# TOP_AURORA_TX register map
Vendor: Texas Instruments
Peripheral module from a debugger description file (folder awr29xx).
Registers are 32-bit, read-write, no defined reset value unless marked. A register's access mark holds for its fields unless they carry their own. Offsets are as the file gives them; lines under a group give offsets from that group; [hi:lo] are bit positions; {n}, {i} and the like mark numbered series; 'fields as' and 'values as' point back to an identical list; <NAME> marks a mode.

## TOP_AURORA_TX
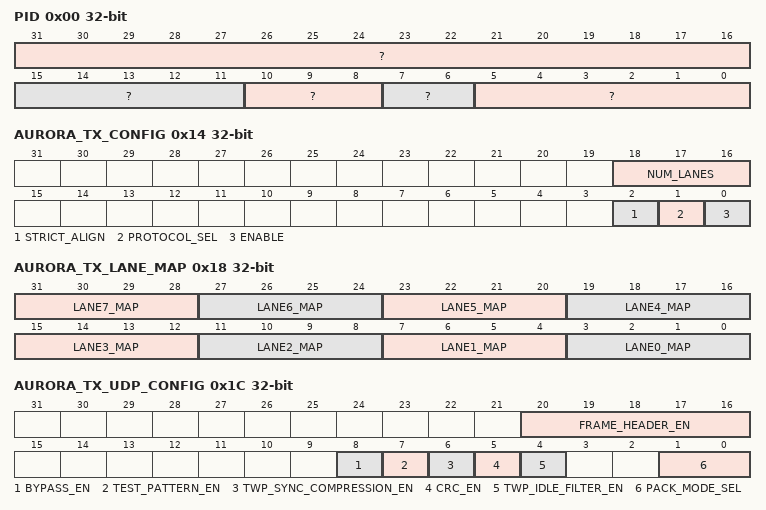
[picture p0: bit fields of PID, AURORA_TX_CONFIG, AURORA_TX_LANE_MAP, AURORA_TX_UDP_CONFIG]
0x00 PID ro
  [31:16] ?, [15:11] ?, [10:8] ?, [7:6] ?, [5:0] ?
0x14 AURORA_TX_CONFIG
  [18:16] NUM_LANES — Selects the number of lanes for trasnmission 0 : 1 Lane 1 : 2 Lanes 7 : 8Lanes
  [2] STRICT_ALIGN — Enable Aurora Strict Alingment Rules
  [1] PROTOCOL_SEL — Selects if the IP is in 8b/10b OR 64b/66b mode. 0 : 8b/10b 1 : 64b/66b
  [0] ENABLE — Selects if the IP is in 8b/10b OR 64b/66b mode. 0 : 8b/10b 1 : 64b/66b
0x18 AURORA_TX_LANE_MAP
  [31:28] LANE7_MAP — These 3 bits determine the logical lane that is transported over the physical lane 7. 000 : Logical lane 0 is transported over physical lane 7 001 : Logical lane 1 is transported over physical lane 7. .. 111 : Logical lane 7 is transported over physical lane 7.
  [27:24] LANE6_MAP — These 3 bits determine the logical lane that is transported over the physical lane 6. 000 : Logical lane 0 is transported over physical lane 6 001 : Logical lane 1 is transported over physical lane 6. .. 111 : Logical lane 7 is transported over physical lane 6.
  [23:20] LANE5_MAP — These 3 bits determine the logical lane that is transported over the physical lane 5. 000 : Logical lane 0 is transported over physical lane 5 001 : Logical lane 1 is transported over physical lane 5. .. 111 : Logical lane 7 is transported over physical lane 5.
  [19:16] LANE4_MAP — These 3 bits determine the logical lane that is transported over the physical lane 4. 000 : Logical lane 0 is transported over physical lane 4. 001 : Logical lane 1 is transported over physical lane 4. .. 111 : Logical lane 7 is transported over physical lane 4.
  [15:12] LANE3_MAP — These 3 bits determine the logical lane that is transported over the physical lane 3. 000 : Logical lane 0 is transported over physical lane 3 001 : Logical lane 1 is transported over physical lane 3. .. 111 : Logical lane 7 is transported over physical lane 3.
  [11:8] LANE2_MAP — These 3 bits determine the logical lane that is transported over the physical lane 2. 000 : Logical lane 0 is transported over physical lane 2 001 : Logical lane 1 is transported over physical lane 2. .. 111 : Logical lane 7 is transported over physical lane 2.
  [7:4] LANE1_MAP — These 3 bits determine the logical lane that is transported over the physical lane 1. 000 : Logical lane 0 is transported over physical lane 1 001 : Logical lane 1 is transported over physical lane 1. .. 111 : Logical lane 7 is transported over physical lane 1.
  [3:0] LANE0_MAP — These 3 bits determine the logical lane that is transported over the physical lane 0. 000 : Logical lane 0 is transported over physical lane 0. 001 : Logical lane 0 is transported over physical lane 1 .. 111 : Logical lane 7 is transported over physical lane 0.
0x1C AURORA_TX_UDP_CONFIG
  [20:16] FRAME_HEADER_EN — Header Enable configuration 0x0 : Disable Header transmission 0x1 - 0x10 : Number of 32 bit Header to be transmmited
  [8] BYPASS_EN — Writing a value of 1'b1 : Bypass the aurora protocol. - No aurora framing is done 1'b0 : Normal Mode - Framing is done as per aurora protocol
  [7] TEST_PATTERN_EN — Writing a value of 1'b1: Enable the test pattern generation when the aurora transmitter is in IDLE state.
  [6] TWP_SYNC_COMPRESSION_EN — Writing a value of 1'b1 : Enables the compression of incoming synchronisation packets. This allows only a configurable number of TWP synchronization packets define by AURORA_TX_TWP_SYNC_CNT::AURORA_TX_TWP_SYNC_CNT_SYNC_CNT to be send through aurora interface. 1'b0 : Disable the TWP padding packet filter.
  [5] CRC_EN — Writing a value of 1'b1 : Enable the UDP CRC calculation 1'b0 : Disable UDP CRC calculation
  [4] TWP_IDLE_FILTER_EN — Writing a value of 1'b1 : Filters out the incoming TWP Padding Packet from being send via aurora interface. 1'b0 : Disable the TWP padding packet filter.
  [1:0] PACK_MODE_SEL — Configure to select AURORATX_UDP_SIZE format 0: Number of TWP Packets 1 : Number of Bytes 3: SW only
0x20 AURORA_TX_UDP_SIZE
  [31:0] SIZE — Configure the number of TWP packets or data bytes to be sent as one packet based on AURORATX_CTRL::PACK_MODE. If PACK_MODE=1 Value configure should be multiple of 4 Bytes.
{0x24+4i} AURORA_TX_UDP_FRAME_HEADER{i} (i=0..15)
  [31:0] DATA — 32 bit DATA Sent out as Frame Header
0x64 AURORA_TX_UFC_MSG_CTRL
  [0] UFC_MSG_SENT_STS — This bit indicates that the message send triggered by the SEND_MSG bit has been completed. Read 1 : Either a hardware or software UFC event occurred. Read 0 : No UFC event occurred. Write 0 : No effect. Write 1 : Clears this bit. This bit is reset when the SEND_MSG bit is set.
0x68 AURORA_TX_UFC_MESSAGE0
  [31:0] MESSAGE0 — This register contains the octets 0 through 3 of the UFC message. All octets have a default value of 0x0A.
0x6C AURORA_TX_UFC_MESSAGE1
  [31:0] MESSAGE1 — This register contains the octets 4 through 7 of the UFC message. All octets have a default value of 0x0A.
0x70 AURORA_TX_TWP_SYNC_CNT
  [9:0] SYNC_CNT — Number of TWP Sync Packet that would be sent if AURORA_TX_UDP_CONFIG::A_TX_UDP_CONFIG_TWP_SYNC_COMPRESSION_EN is 0x1. (Min Value 2)
0x80 AURORA_TX_INITIALIZE_REQ
  [1] TX_INIT — The single bit input to trigger the initialization sequence. Asserting this bit starts Tx process.
0x84 AURORA_TX_UFC_MSG_REQ
  [0] SEND_MSG — The bit that triggers the controller to send the MESSAGE0 and MESSAGE1 register contents as a UFC packet.
0x88 AURORA_TX_FLUSH_REQ
  [0] TRIGGER — Selects the number of lanes for trasnmission 0 : 1 Lane 1 : 2 Lanes 7 : 8Lanes
0x8C AURORA_TX_EOP_REQ
  [0] TRIGGER — SW End of Packet trigger to aurora dataframer.
0x90 AURORA_TX_DATA_START_REQ
  [1] DATA_START — The single bit input to trigger the initialization sequence. Asserting this bit starts Tx process.
0x94 AURORA_TX_DATA_STOP_REQ
  [1] DATA_STOP — The single bit input to trigger the Start of Data Transmission
0x98 AURORA_TX_TESTPATTERN_START_REQ
  [1] TEST_PATTERN_START — The single bit input to trigger the Stop of Data Transmission
0x9C AURORA_TX_TESTPATTERN_STOP_REQ
  [1] TEST_PATTERN_STOP — The single bit input to trigger the Start of TestPattern Transmission
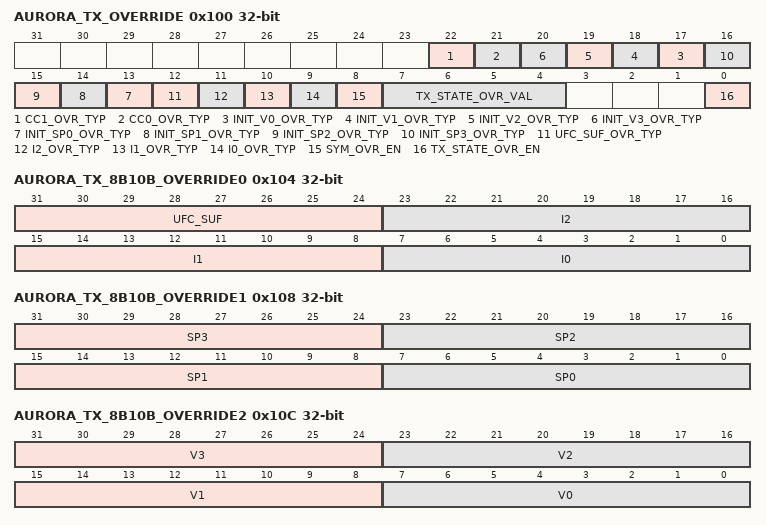
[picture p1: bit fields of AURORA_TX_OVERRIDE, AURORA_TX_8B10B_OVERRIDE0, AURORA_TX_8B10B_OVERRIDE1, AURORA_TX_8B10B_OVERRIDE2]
0x100 AURORA_TX_OVERRIDE
  [22] CC1_OVR_TYP — This read write bit indicates whether the CC1_OVR_TYP symbol is a /D/ octet or /K/ octet. 1 : Indicates a /K/ octet. 0 : Indicates a /D/ octet.
  [21] CC0_OVR_TYP — This read write bit indicates whether the CC0_OVR_TYP symbol is a /D/ octet or /K/ octet. 1 : Indicates a /K/ octet. 0 : Indicates a /D/ octet.
  [n+17] INIT_V{n}_OVR_TYP (n=0..3) — This read write bit indicates whether the INIT_V{n}_OVR_TYP symbol is a /D/ octet or /K/ octet. 1 : Indicates a /K/ octet. 0 : Indicates a /D/ octet.
  [n+13] INIT_SP{n}_OVR_TYP (n=0..3) — This read write bit indicates whether the INIT_SP{n}_OVR_TYP symbol is a /D/ octet or /K/ octet. 1 : Indicates a /K/ octet. 0 : Indicates a /D/ octet.
  [12] UFC_SUF_OVR_TYP — This read write bit indicates whether the UFC_SUF_OVR_TYP symbol is a /D/ octet or /K/ octet. 1 : Indicates a /K/ octet. 0 : Indicates a /D/ octet.
  [11] I2_OVR_TYP — This read write bit indicates whether the I2_OVR symbol is a /D/ octet or /K/ octet. 1 : Indicates a /K/ octet. 0 : Indicates a /D/ octet.
  [10] I1_OVR_TYP — This read write bit indicates whether the I1_OVR symbol is a /D/ octet or /K/ octet. 1 : Indicates a /K/ octet. 0 : Indicates a /D/ octet.
  [9] I0_OVR_TYP — This read write bit indicates whether the I0_OVR symbol is a /D/ octet or /K/ octet. 1 : Indicates a /K/ octet. 0 : Indicates a /D/ octet.
  [8] SYM_OVR_EN — This read write bit allows the symbols used in the various sequences to be overridden with the values used in the AURORA_TX_SYM register.
  [7:4] TX_STATE_OVR_VAL — These bits take effect to enforce a certain transmission state if the TX_ST_OVR_EN bit is set. The states are enforced as per the following bit values: 0000 : Reset, no transmission. 0001 : Initialization 0010 : Clock Compensation 0011 : Idle 0100 : UFC 0101 : Run (data) 0110 : Test (data) 0111 : Reserved . 1111 : Reserved
  [0] TX_STATE_OVR_EN — This read write bit allows the user to force the IP to remain in a given transmission state. The enforced transmission state is defined by the TX_ST_OVR bits.
0x104 AURORA_TX_8B10B_OVERRIDE0
  [31:24] UFC_SUF — The 8B/10B protocol defines Start of User Flow Control PDU symbol /SUF/. The value defined in the octet here allows this value to be overridden. The value defined here will be effective whenever the User Flow Control packet is transmitted. Default value of this octet is /SUF/ (/SUF/ <=> /K28.4/ <=> 0x9C). This value is effective only if the SYM_OVR_EN bit in the AURORA_TX_OVERRIDE register is set.
  [23:16] I2 — The 8B/10B protocol defines three symbols - /K/, /R/ and /A/ that can be used in the Idle (/I/) sequence. The value defined here will be effective whenever the Idle sequence is used during any transmission state. Default value of this octet is /R/ (/R/ <=> /K28.0/ <=> 0x1C). This value is effective only if the SYM_OVR_EN bit in the AURORA_TX_OVERRIDE register is set.
  [15:8] I1 — The 8B/10B protocol defines three symbols - /K/, /R/ and /A/ that can be used in the Idle (/I/) sequence. The value defined in the octet here allows one of the three to be overridden. The value defined here will be effective whenever the Idle sequence is used during any transmission state. Default value of this octet is /K/ (/K/ <=> /K28.5/ <=> 0xBC). This value is effective only if the SYM_OVR_EN bit in the AURORA_TX_OVERRIDE register is set.
  [7:0] I0 — The 8B/10B protocol defines three symbols - /K/, /R/ and /A/ that can be used in the Idle (/I/) sequence. The value defined here will be effective whenever the Idle sequence is used during any transmission state. Default value of this octet is /A/ (/A/ <=> /K28.3/ <=> 0x7C). This value is effective only if the SYM_OVR_EN bit in the AURORA_TX_OVERRIDE register is set.
0x108 AURORA_TX_8B10B_OVERRIDE1
  [31:24] SP3 — The 8B/10B protocol defines the /D10.2/ as the fourth octet to be used in the Sync Polarity (/SP/) sequence during lane initialization. The value defined in the octet here allows the fourth octet to be overridden. Default value of this octet is /D10.2/ <=> 0x4A. This value will be effective whenever the Sync Polarity sequence is used during the INIT transmission state. This value is effective only if the SYM_OVR_EN bit in the AURORA_TX_OVERRIDE register is set.
  [23:16] SP2 — The 8B/10B protocol defines the /D10.2/ as the third octet to be used in the Sync Polarity (/SP/) sequence during lane initialization. The value defined in the octet here allows the third octet to be overridden. Default value of this octet is /D10.2/ <=> 0x4A. This value will be effective whenever the Sync Polarity sequence is used during the INIT transmission state. This value is effective only if the SYM_OVR_EN bit in the AURORA_TX_OVERRIDE register is set.
  [15:8] SP1 — The 8B/10B protocol defines the /D10.2/ as the second octet to be used in the Sync Polarity (/SP/) sequence during lane initialization. The value defined in the octet here allows the second octet to be overridden. Default value of this octet is /D10.2/ <=> 0x4A. This value will be effective whenever the Sync Polarity sequence is used during the INIT transmission state. This value is effective only if the SYM_OVR_EN bit in the AURORA_TX_OVERRIDE register is set.
  [7:0] SP0 — The 8B/10B protocol defines the /K28.5/ as the first octet to be used in the Sync Polarity (/SP/) sequence during lane initialization. The value defined in the octet here allows the first octet to be overridden. Default value of this octet is /K28.5/ <=> 0xBC. This value will be effective whenever the Sync Polarity sequence is used during the INIT transmission state. This value is effective only if the SYM_OVR_EN bit in the AURORA_TX_OVERRIDE register is set.
0x10C AURORA_TX_8B10B_OVERRIDE2
  [31:24] V3 — The 8B/10B protocol defines the /D8.7/ as the fourth octet to be used in the Verification sequence during lane initialization. The value defined in the octet here allows the fourth octet to be overridden. Default value of this octet is /D8.7/ <=> 0xE8. This value will be effective whenever the Verification sequence is used during the INIT transmission state. This value is effective only if the SYM_OVR_EN bit in the AURORA_TX_OVERRIDE register is set.
  [23:16] V2 — The 8B/10B protocol defines the /D8.7/ as the third octet to be used in the Verification sequence during lane initialization. The value defined in the octet here allows the third octet to be overridden. Default value of this octet is /D8.7/ <=> 0xE8. This value will be effective whenever the Verification sequence is used during the INIT transmission state. This value is effective only if the SYM_OVR_EN bit in the AURORA_TX_OVERRIDE register is set.
  [15:8] V1 — The 8B/10B protocol defines the /D8.7/ as the second octet to be used in the Verification sequence during lane inititialization. The value defined in the octet here allows the second octet to be overridden. Default value of this octet is /D8.7/ <=> 0xE8. This value will be effective whenever the Verification sequence is used during the INIT transmission state. This value is effective only if the SYM_OVR_EN bit in the AURORA_TX_OVERRIDE register is set.
  [7:0] V0 — The 8B/10B protocol defines the /K28.5/ as the first octet to be used in the Verification sequence during lane inititialization. The value defined in the octet here allows the first octet to be overridden. Default value of this octet is /K28.5/ <=> 0xBC. This value will be effective whenever the Verification sequence is used during the INIT transmission state. This value is effective only if the SYM_OVR_EN bit in the AURORA_TX_OVERRIDE register is set.
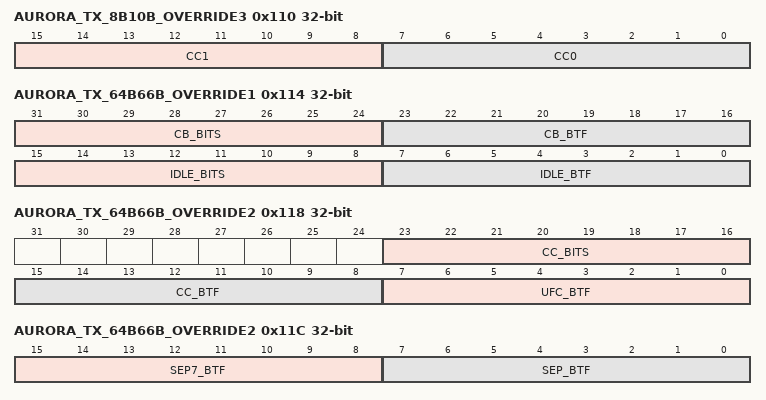
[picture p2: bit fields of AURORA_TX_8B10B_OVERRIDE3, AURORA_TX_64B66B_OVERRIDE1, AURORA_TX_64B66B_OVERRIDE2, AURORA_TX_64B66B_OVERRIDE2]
0x110 AURORA_TX_8B10B_OVERRIDE3
  [15:8] CC1 — The 8B/10B protocol defines the /K23.7/ as the second octet to be used in the Clock Compensation sequence. The value defined in the octet here allows the second octet to be overridden. Default value of this octet is /K23.7/ <=> 0xF7. This value will be effective whenever the Verification sequence is used during the Clock Compensation transmission state. This value is effective only if the SYM_OVR_EN bit in the AURORA_TX_OVERRIDE register is set.
  [7:0] CC0 — The 8B/10B protocol defines the /K23.7/ as the first octet to be used in the Clock Compensation sequence. The value defined in the octet here allows the first octet to be overridden. Default value of this octet is /K23.7/ <=> 0xF7. This value will be effective whenever the Verification sequence is used during the Clock Compensation transmission state. This value is effective only if the SYM_OVR_EN bit in the AURORA_TX_OVERRIDE register is set.
0x114 AURORA_TX_64B66B_OVERRIDE1
  [31:24] CB_BITS — The 64B/66B protocol defines the CC, CB, NR, SA bits for all the type of Idle Blocks. This field may be overriden with the values defined here. These bits are used during Channel Bonding. Bit 8 overrides the CC bit (bit 10 of 64B/66B block code), Bit 9 overrides the CB bit (bit 11 of 64B/66B block code), Bit 10 overrides the NR bit (bit 12 of 64B/66B block code), Bit 11 overrides the SA bit (bit 13 of 64B/66B block code), Bits 12:15 override the '0000' bits (bits [14:17] of 64B/66B block code). This field is effective only if the SYM_OVR_EN bit in the AURORA_TX_OVERRIDE register is set. This field is applicable only in the 64B/66B protocol mode.
  [23:16] CB_BTF — The 64B/66B protocol defines the value of 0x78 as the BTF for all the types of Idle code blocks. The value given in this field may be used to override the BTF for the Channel Bonding code blocks. This value is effective only if the SYM_OVR_EN bit in the AURORA_TX_OVERRIDE register is set. This field is applicable only in the 64B/66B protocol mode.
  [15:8] IDLE_BITS — The 64B/66B protocol defines the CC, CB, NR, SA bits for all the type of Idle Blocks. This field may be overriden with the values defined here. Bit 8 overrides the CC bit (bit 10 of 64B/66B block code), Bit 9 overrides the CB bit (bit 11 of 64B/66B block code), Bit 10 overrides the NR bit (bit 12 of 64B/66B block code), Bit 11 overrides the SA bit (bit 13 of 64B/66B block code), Bits 12:15 override the '0000' bits (bits [14:17] of 64B/66B block code). This field is effective only if the SYM_OVR_EN bit in the AURORA_TX_OVERRIDE register is set. This field is applicable only in the 64B/66B protocol mode.
  [7:0] IDLE_BTF — The 64B/66B protocol defines the value of 0x78 as the BTF for all the types of Idle code blocks. The value given in this field may be used to override the BTF for the Idle code blocks. This value is effective only if the SYM_OVR_EN bit in the AURORA_TX_OVERRIDE register is set. This field is applicable only in the 64B/66B protocol mode.
0x118 AURORA_TX_64B66B_OVERRIDE2
  [23:16] CC_BITS — The 64B/66B protocol defines the CC, CB, NR, SA bits for all the type of Channel Bonding Blocks. This field may be overriden with the values defined here. These bits are used during the Clock Compensation block transmission. Bit 8 overrides the CC bit (bit 10 of 64B/66B block code), Bit 9 overrides the CB bit (bit 11 of 64B/66B block code), Bit 10 overrides the NR bit (bit 12 of 64B/66B block code), Bit 11 overrides the SA bit (bit 13 of 64B/66B block code), Bits 12:15 override the '0000' bits (bits [14:17] of 64B/66B block code). This field is effective only if the SYM_OVR_EN bit in the AURORA_TX_OVERRIDE register is set. This field is applicable only in the 64B/66B protocol mode.
  [15:8] CC_BTF — The 64B/66B protocol defines the value of 0x78 as the BTF for all the types of Idle code blocks. The value given in this field may be used to override the BTF for the Clock Compensation code blocks. This value is effective only if the SYM_OVR_EN bit in the AURORA_TX_OVERRIDE register is set. This field is applicable only in the 64B/66B protocol mode.
  [7:0] UFC_BTF — The 64B/66B protocol defines the value of 0x2D as the BTF for the UFC code block. The value given in this field may be used to override the BTF for the UFC code block. This value is effective only if the SYM_OVR_EN bit in the AURORA_TX_OVERRIDE register is set. This field is applicable only in the 64B/66B protocol mode.
0x11C AURORA_TX_64B66B_OVERRIDE2
  [15:8] SEP7_BTF — The 64B/66B protocol defines the value of 0xE1 as the BTF for the Separator-7. The value given in this field may be used to override the BTF for Separator-7. This value is effective only if the SYM_OVR_EN bit in the AURORA_TX_OVERRIDE register is set. This field is applicable only in the 64B/66B protocol mode.
  [7:0] SEP_BTF — The 64B/66B protocol defines the value of 0x1E as the BTF for the Separator. The value given in this field may be used to override the BTF for Separator. This value is effective only if the SYM_OVR_EN bit in the AURORA_TX_OVERRIDE register is set. This field is applicable only in the 64B/66B protocol mode.
0x124 AURORA_TX_INIT_CNT_LRC
  [31:0] LRC_N — The 32-bit count value used to move from the TXRESET1 state to the TXINIT0 state. This value indicates the number of times the /SP/ sequence is sent in the TXRESET1 state.
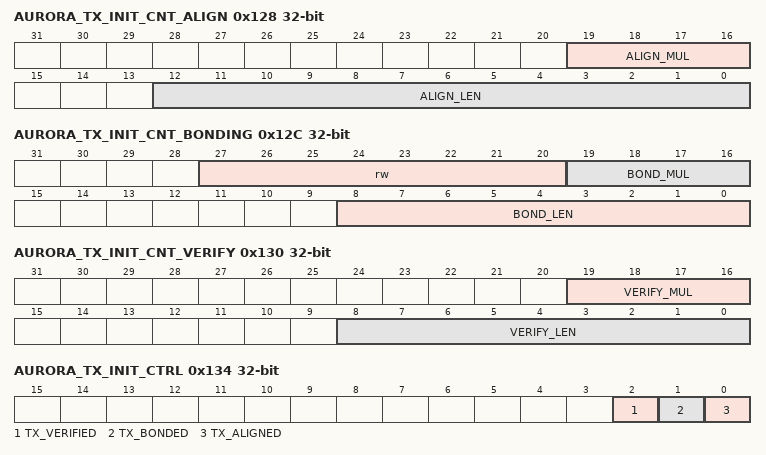
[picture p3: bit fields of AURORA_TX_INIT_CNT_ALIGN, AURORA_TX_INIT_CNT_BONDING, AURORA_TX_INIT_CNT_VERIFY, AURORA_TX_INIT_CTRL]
0x128 AURORA_TX_INIT_CNT_ALIGN
  [19:16] ALIGN_MUL — Alignment pattern multiplier. Defines the multiplier used in conjunction with ALIGN_LEN when performing link initialization. 0000b: Alignment pattern multiplier is 32. 0001b: Reserved. 0010b: Reserved. 0011b: Reserved. 0100b: Reserved. Otherwise Alignment pattern multiplier is 2n, where n is the value of this field.
  [12:0] ALIGN_LEN — The number of times the Aurora alignment pattern is sent. Number of patterns = ALIGN_MUL*(ALIGN_LEN + 1).
0x12C AURORA_TX_INIT_CNT_BONDING
  [27:20] rw — The 64B standard mentions that There must be at least four Idle blocks between each Channel Bonding block. in Table 4-1 of the 4.2.1 Lane Initialization section. The user could specify 1 to 16 Idle blocks between the Channel Bonding block. It is not recommended to use less than 4 Idle Blocks between the Channel Bonding blocks. The default value of this field at reset is 4. Permissible values: 8'h01 : No of Idle Blocks between Channel Bonding blocks = 1 8'h02 : No of Idle Blocks between Channel Bonding blocks = 2 8'hFF : No of Idle Blocks between Channel Bonding blocks = 255 Do not program 8'h00.
  [19:16] BOND_MUL — Bond pattern multiplier. Defines the multiplier used in conjunction with BOND_LEN when performing link initialization. 0000b: Bond pattern multiplier is 4. 0001b: Reserved. Otherwise Bond pattern multiplier is 2n, where n is the value of this field.
  [8:0] BOND_LEN — The number of times the Aurora bonding pattern is sent. Number of patterns = BOND_MUL*(BOND_LEN + 1).
0x130 AURORA_TX_INIT_CNT_VERIFY
  [19:16] VERIFY_MUL — Verify pattern multiplier. Defines the multiplier used in conjunction with VERIFY_LEN when performing link initialization. 0000b: Verify pattern multiplier is 4. 0001b: Reserved. Otherwise Verify pattern multiplier is 2n, where n is the value of this field.
  [8:0] VERIFY_LEN — The number of times the Aurora verification pattern is sent. Number of patterns = VERIFY_MUL*(VERIFY_LEN + 1).
0x134 AURORA_TX_INIT_CTRL
  [2] TX_VERIFIED — The single bit input to trigger the transition from the verification state to the channel ready state.
  [1] TX_BONDED — The single bit input to trigger the transition from the bonding to the verification state.
  [0] TX_ALIGNED — The single bit input to trigger the Stop of TestPattern Transmission
0x138 AURORA_TX_IDLE_CTRL
  [5:2] SEED — The 4-bit value used to seed the pseudo random integer used in the idle sequence generator.
0x13C AURORA_TX_IDLE_REQ
  [0] SEND_IDLE — This bit is used to trigger the insertion of the IDLE sequence by the software. The IDLE FSM will insert the IDLE sequence octets at the earliest possible opportunity.
0x140 AURORA_TX_CC_REQ
  [1] SEND_CC — The single bit input that can trigger a CC sequence. The internal FSM will insert a CC sequence at the earliest possible opportunity.
0x144 AURORA_TX_CC_CNT
  [15:0] SYNC_COUNT — The 16-bit count value used to indicate the number of code group octets after which the CC sequence should be transmitted. Default is 0x26FC (decimal 9980) and increasing the period beyond this value is not advised as corruption of data can occur.
0x148 AURORA_TX_CB_STATUS
  [0] CB_COMP — This bit reflects the state of the Channel Bonding FSM. Read 0 : CB Block is not complete. Read 1 : CB Block is complete. Write 0 : No effect. Write 1 : Clears the bit. Setting the SEND_CB bit also clears this bit. This bit is applicable only in the 64B/66B protocol mode after the Channel Ready state has been reached.
0x14C AURORA_TX_CB_REQ
  [1] SEND_CB — The single bit input that can trigger a Channel Bonding Block. The internal FSM will insert a Channel Bonding sequence at the earliest possible opportunity. This bit is applicable only in the 64B/66B protocol mode after the Channel Ready state has been reached.
0x150 AURORA_TX_CB_CNT
  [15:0] CB_COUNT — The 16-bit count value used to indicate the number of data blocks after which the Channel Bonding sequence should be transmitted. The default value is 0x4E20 (decimal 20000). A value of zero will ensure that the Channel Bonding sequence is not sent periodically. In this case, the Channel Bonding sequence can only be sent by setting the SEND_CB bit in the AURORA_TX_CB_REQ register. This bit is applicable only in the 64B/66B protocol mode after the Channel Ready state has been reached.
0x154 AURORA_TX_RESET_REQ
  [0] TX_RESET — The single bit input to reset the Tx process. Asserting this bit brings all internal FSMs to their reset state. (The TX_INIT bit must be asserted for the FSMs to continue to their next states after the reset state.)
0x158 AURORA_TX_SERIALIZER_OVERRIDE0
  [31:0] val — Serialzer Override Value0 for Debug/Legacy modes. This value is not expected tp be changed
0x15C AURORA_TX_SERIALIZER_OVERRIDE1
  [31:0] val — Serialzer Override Value1 for Debug/Legacy modes. This value is not expected tp be changed
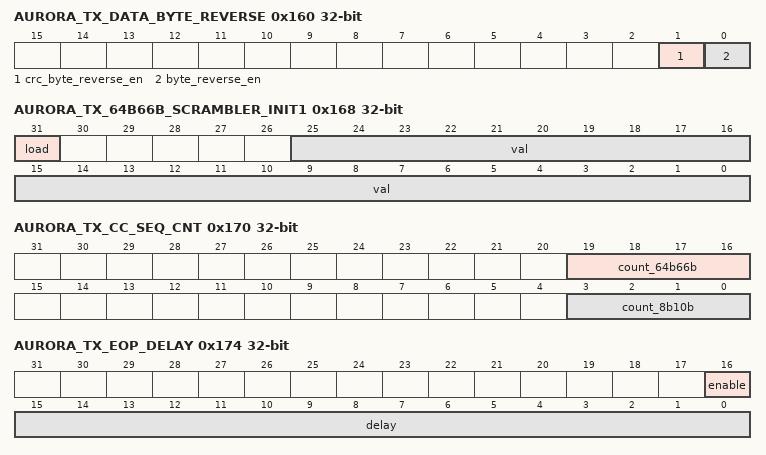
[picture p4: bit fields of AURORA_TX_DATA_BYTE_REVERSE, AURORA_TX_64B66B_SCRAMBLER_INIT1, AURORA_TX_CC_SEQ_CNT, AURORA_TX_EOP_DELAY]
0x160 AURORA_TX_DATA_BYTE_REVERSE
  [1] crc_byte_reverse_en — Enable Byte reversal on the CRC value.
  [0] byte_reverse_en — Enable Byte reversal on the input data. Aplicable only on the data from TPIU and Testpattern
0x164 AURORA_TX_64B66B_SCRAMBLER_INIT0
  [31:0] val — Initial value in the LFSR scrambler bits[31:0]
0x168 AURORA_TX_64B66B_SCRAMBLER_INIT1
  [31] load — Write 0x1 to loaf the scrambler lfsr init value
  [25:0] val — Initial value in the LFSR scrambler bits[57:32]
0x16C AURORA_TX_TESTPATTERN_CTRL
  [0] ramp_en — Enable a ramp patten as the testpattern
0x170 AURORA_TX_CC_SEQ_CNT
  [19:16] count_64b66b — Configure the number of 64b66b Clock Compensation block to be sent. The default value is as per the Aurora Spec. This is intented for Debug purposes only.
  [3:0] count_8b10b — Configure the number of 8b10b Clock Compensation octets to be sent. The default value is as per the Aurora Spec. This is intented for Debug purposes only.
0x174 AURORA_TX_EOP_DELAY
  [16] enable — Write 0x1 to this fiel to enable the delay configured in AURORA_TX_EOP_DEALY::DELAY
  [15:0] delay — Internal Delay between the Data Framer and the Controller Block to stall data to the controller and force IDLES to be inserted by the controller after an ECP of a UDP. This is a feature added for Debug Purposes only and has not been tested
0x178 AURORA_TX_FLUSH_DELAY
  [7:0] delay — Write 0x1 to this fiel to enable the delay configured in AURORA_TX_EOP_DEALY::DELAY
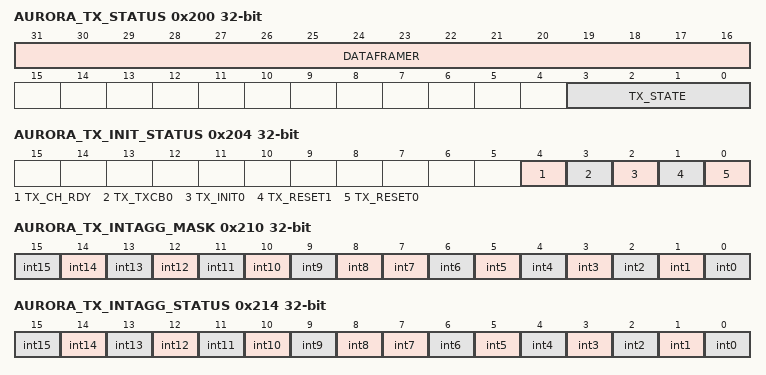
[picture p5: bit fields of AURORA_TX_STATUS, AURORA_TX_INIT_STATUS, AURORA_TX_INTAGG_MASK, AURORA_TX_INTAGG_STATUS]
0x200 AURORA_TX_STATUS ro
  [31:16] DATAFRAMER — Dataframer Status fields Bit 16 : Write on Full FIFO Bit 17 : Read on Empty FIFO Bits [20:18] : Run State 000 : OFF 001 : INIT DONE 010 : TEST MODE 011 : DATA MODE 100 : WAITING FOR GLOBAL FLUSH DONE 101 : FLUSH IN PROGRESS Bits [26:21] : Data Available in Internal FIFO
  [3:0] TX_STATE — These read only bits indicate the state of the transmitter in 8B/10B and 64B/66B. 0000 : Reset, no transmission. 0001 : Initialization 0010 : Clock Compensation 0011 : Idle 0100 : UFC 0101 : Run (data) 0110 : Test (data) 0111 : Reserved . 1111 : Reserved The user must note that these bits reflect the controller state and that the actual octets on the PHY lines may differ due to internal data path latencies.
0x204 AURORA_TX_INIT_STATUS ro
  [4] TX_CH_RDY — The status bit that indicates that the channel ready state has been reached. This bit is reset with the device reset and when the TX_RESET bit is set.
  [3] TX_TXCB0 — The status bit that indicates that the TX_ TXCB0 state has been completed. This bit is reset with the device reset and when the TX_RESET bit is set.
  [2] TX_INIT0 — The status bit that indicates that the TX_INIT0 state has been completed. This bit is reset with the device reset and when the TX_RESET bit is set.
  [1] TX_RESET1 — The status bit that indicates that the TX_RESET1 state has been completed. This bit is reset with the device reset and when the TX_RESET bit is set.
  [0] TX_RESET0 — The status bit that indicates that the TX_RESET0 state has been completed. This bit is reset with the device reset and when the TX_RESET bit is set.
0x208 AURORA_TX_CC_STATUS
  [0] CC_COMP — This bit reflects the state of the CC FSM. Read 0 : CC sequence is not complete. Read 1 : CC sequence is complete. Write 0 : No effect. Write 1 : Clears the bit. Setting the SEND_CC bit also clears this bit.
0x20C AURORA_TX_IDLE_STATUS
  [0] IDLE_COMP — This bit reflects the state of the IDLE FSM. Read 0 : IDLE sequence is not complete. Read 1 : IDLE sequence is complete. Write 0 : No effect. Write 1 : Clears the bit. Setting the SEND_IDLE bit also clears this bit.
0x210 AURORA_TX_INTAGG_MASK
  [n] int{n} (n=8..15) — Mask the the corresponding event line from generating an Interrupt. This field masks the interrupt from Event {n}
  [7] int7 — Mask Interrupt AURORA_TX_HEADER_DONE 1 : Interrupt is Masked 0 : Interrupt is Unmasked
  [6] int6 — Mask Interrupt AURORA_TX_EOP_DONE 1 : Interrupt is Masked 0 : Interrupt is Unmasked
  [5] int5 — Mask Interrupt DATA_STOP_DONE 1 : Interrupt is Masked 0 : Interrupt is Unmasked
  [4] int4 — Mask Interrupt AURORA_TX_CC_DONE 1 : Interrupt is Masked 0 : Interrupt is Unmasked
  [3] int3 — Mask Interrupt AURORA_TX_UFC_SENT 1 : Interrupt is Masked 0 : Interrupt is Unmasked
  [2] int2 — Mask Interrupt AURORA_TX_EXT_FLUSH_DONE 1 : Interrupt is Masked 0 : Interrupt is Unmasked
  [1] int1 — Mask Interrupt AURORA_TX_FLUSH_DONE 1 : Interrupt is Masked 0 : Interrupt is Unmasked
  [0] int0 — Mask Interrupt AURORA_TX_INIT_DONE 1 : Interrupt is Masked 0 : Interrupt is Unmasked
0x214 AURORA_TX_INTAGG_STATUS
  [n] int{n} (n=8..15) — Read of 0x1 indicates a rising edge was detected on the corresponding event line . This field indicates assertion of Event {n}
  [7] int7 — Read of 0x1 indicates a rising edge was detected on the corresponding event line . This field indicates assertion of AURORA_TX_HEADER_DONE.
  [6] int6 — Read of 0x1 indicates a rising edge was detected on the corresponding event line . This field indicates assertion of AURORA_TX_EOP_DONE.
  [5] int5 — Read of 0x1 indicates a rising edge was detected on the corresponding event line . This field indicates assertion of DATA_STOP_DONE.
  [4] int4 — Read of 0x1 indicates a rising edge was detected on the corresponding event line . This field indicates assertion of AURORA_TX_CC_DONE
  [3] int3 — Read of 0x1 indicates a rising edge was detected on the corresponding event line . This field indicates assertion of AURORA_TX_UFC_SENT.
  [2] int2 — Read of 0x1 indicates a rising edge was detected on the corresponding event line . This field indicates assertion of AURORA_TX_EXT_FLUSH_DONE
  [1] int1 — Read of 0x1 indicates a rising edge was detected on the corresponding event line . This field indicates assertion of AURORA_TX_FLUSH_DONE
  [0] int0 — Read of 0x1 indicates a rising edge was detected on the corresponding event line . This field indicates assertion of AURORA_TX_INIT_DONE
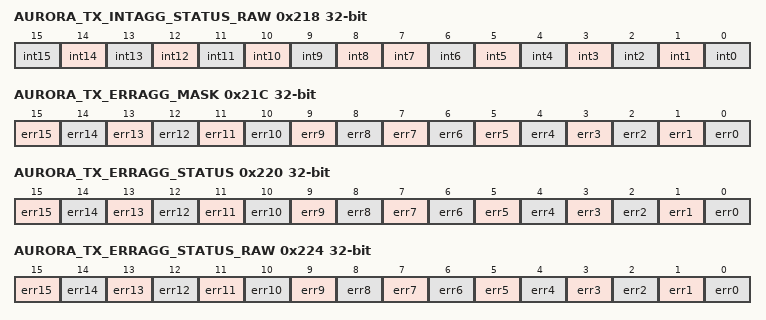
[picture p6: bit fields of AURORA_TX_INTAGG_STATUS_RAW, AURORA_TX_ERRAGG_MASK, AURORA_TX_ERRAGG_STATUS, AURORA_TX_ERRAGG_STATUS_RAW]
0x218 AURORA_TX_INTAGG_STATUS_RAW
  [n] int{n} (n=8..15) — Read of 0x1 indicates a rising edge was detected on the corresponding event line . This is the raw status that will be asserted even if the event has been masked in AURORA_TX_INTAGG_MASK. This field indicates assertion of Event {n}
  [7] int7 — Read of 0x1 indicates a rising edge was detected on the corresponding event line . This is the raw status that will be asserted even if the event has been masked in AURORA_TX_INTAGG_MASK. This field indicates assertion of AURORA_TX_HEADER_DONE- Indicates completion of Frame Header transmission.
  [6] int6 — Read of 0x1 indicates a rising edge was detected on the corresponding event line . This is the raw status that will be asserted even if the event has been masked in AURORA_TX_INTAGG_MASK. This field indicates assertion of AURORA_TX_EOP_DONE-Indicates completion of UDP packets
  [5] int5 — Read of 0x1 indicates a rising edge was detected on the corresponding event line . This is the raw status that will be asserted even if the event has been masked in AURORA_TX_INTAGG_MASK. This field indicates assertion of DATA_STOP_DONE.
  [4] int4 — Read of 0x1 indicates a rising edge was detected on the corresponding event line . This is the raw status that will be asserted even if the event has been masked in AURORA_TX_INTAGG_MASK. This field indicates assertion of AURORA_TX_CC_DONE-Indicate completion of Clock compensation sequence trasnmission
  [3] int3 — Read of 0x1 indicates a rising edge was detected on the corresponding event line . This is the raw status that will be asserted even if the event has been masked in AURORA_TX_INTAGG_MASK. This field indicates assertion of AURORA_TX_UFC_SENT-Indicates that a UFC packet has been generated as sent
  [2] int2 — Read of 0x1 indicates a rising edge was detected on the corresponding event line . This is the raw status that will be asserted even if the event has been masked in AURORA_TX_INTAGG_MASK. This field indicates assertion of AURORA_TX_EXT_FLUSH_DONE-Indicates that the MDO infrastructure has completed flushing is components
  [1] int1 — Read of 0x1 indicates a rising edge was detected on the corresponding event line . This is the raw status that will be asserted even if the event has been masked in AURORA_TX_INTAGG_MASK. This field indicates assertion of AURORA_TX_FLUSH_DONE -Indicates that the Aurora IP has completed flush operation on its Data FIFO
  [0] int0 — Read of 0x1 indicates a rising edge was detected on the corresponding event line . This is the raw status that will be asserted even if the event has been masked in AURORA_TX_INTAGG_MASK. This field indicates assertion of AURORA_TX_INIT_DONE - Indicates completion of Aurora Initilization sequence
0x21C AURORA_TX_ERRAGG_MASK
  [n] err{n} (n=1..15) — Mask the the corresponding Error event line from generating an Interrupt. This field masks the interrupt from Error event {n}
  [0] err0 — Mask error AURORA_TX_UFC_ERR 1 : Error is Masked 0 : Error is Unmasked
0x220 AURORA_TX_ERRAGG_STATUS
  [n] err{n} (n=1..15) — Read of 0x1 indicates a rising edge was detected on the corresponding Error event line . This field indicates assertion of Error event {n}
  [0] err0 — Read of 0x1 indicates a rising edge was detected on the corresponding Error event line . This field indicates assertion of Error AURORA_TX_UFC_ERR
0x224 AURORA_TX_ERRAGG_STATUS_RAW
  [n] err{n} (n=1..15) — Read of 0x1 indicates a rising edge was detected on the corresponding Error event line . This is the raw status that will be asseter even if the Error event has been masked in AURORA_TX_ERRAGG_MASK. This field indicates assertion of Error event {n}
  [0] err0 — Read of 0x1 indicates a rising edge was detected on the corresponding Error event line . This is the raw status that will be asseter even if the Error event has been masked in AURORA_TX_ERRAGG_MASK. This field indicates assertion of Error AURORA_TX_UFC_ERR - Inidcates that another UFC generation request was received with the IP was in the progress of transmitting the previous request.
0x228 AURORA_TX_SERIALIZER_STATUS0 ro
  [31:0] status — Status of the serializer. For debug purposes only
0x22C AURORA_TX_SERIALIZER_STATUS1 ro
  [31:0] status — Status of the serializer. For debug purposes only
0x230 AURORA_TX_TPIU_DATA_PACKED ro
  [31:0] bytes_packed — Number of input tpiu bytes packed in the current aurora frame
{0xFD0+4i} HW_SPARE_RW{i} (i=0..3)
  [31:0] hw_spare_rw{i} — Reserved for HW R&D
{0xFE0+4i} HW_SPARE_RO{i} ro (i=0..3)
  [31:0] hw_spare_ro{i} — Reserved for HW R&D
0xFF0 HW_SPARE_WPH
  [31:0] hw_spare_wph — Reserved for HW R&D
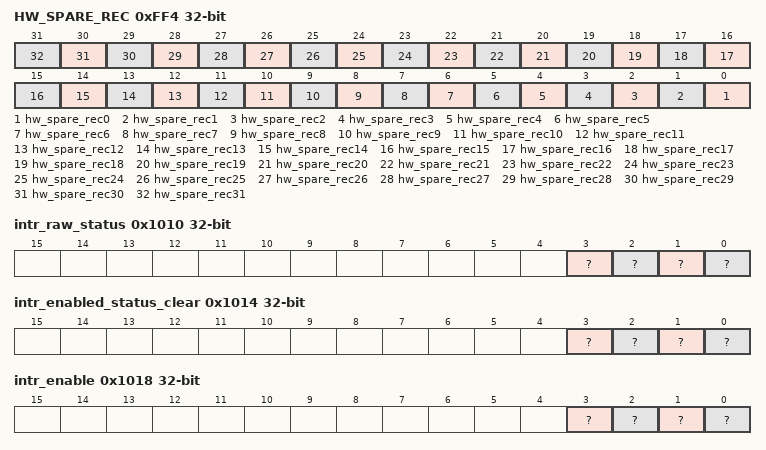
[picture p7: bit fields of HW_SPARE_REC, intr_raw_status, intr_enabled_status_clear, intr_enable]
0xFF4 HW_SPARE_REC
  [n] hw_spare_rec{n} (n=0..31) — Reserved for HW R&D
0x1008 LOCK0_KICK0 — - KICK0 component
  [31:0] ?
0x100C LOCK0_KICK1 — - KICK1 component
  [31:0] ?
0x1010 intr_raw_status — Interrupt Raw Status/Set Register
  [3] ? — Proxy0 access violation error. Raw status is read. Write a 1 to set the status. Writing a 0 has no effect.
  [2] ? — Kick access violation error. Raw status is read. Write a 1 to set the status. Writing a 0 has no effect.
  [1] ? — Addressing violation error. Raw status is read. Write a 1 to set the status. Writing a 0 has no effect.
  [0] ? — Protection violation error. Raw status is read. Write a 1 to set the status. Writing a 0 has no effect.
0x1014 intr_enabled_status_clear — Interrupt Enabled Status/Clear register
  [3] ? — Proxy0 access violation error. Enabled status is read. Write a 1 to clear the status. Writing a 0 has no effect.
  [2] ? — Kick access violation error. Enabled status is read. Write a 1 to clear the status. Writing a 0 has no effect.
  [1] ? — Addressing violation error. Enabled status is read. Write a 1 to clear the status. Writing a 0 has no effect.
  [0] ? — Protection violation error. Enabled status is read. Write a 1 to clear the status. Writing a 0 has no effect.
0x1018 intr_enable — Interrupt Enable register
  [3] ? — Proxy0 access violation error enable. Write a 1 to set the enable. Writing a 0 has no effect.
  [2] ? — Kick access violation error enable. Write a 1 to set the enable. Writing a 0 has no effect.
  [1] ? — Addressing violation error enable. Write a 1 to set the enable. Writing a 0 has no effect.
  [0] ? — Protection violation error enable. Write a 1 to set the enable. Writing a 0 has no effect.
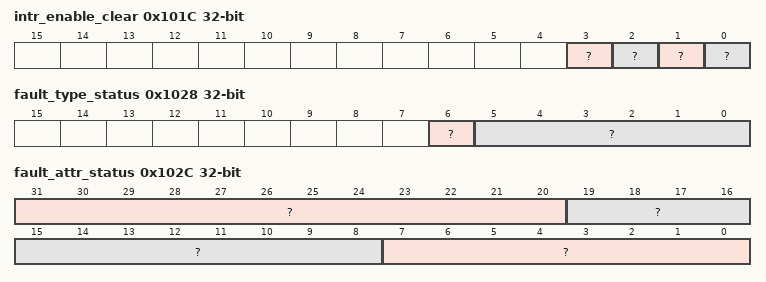
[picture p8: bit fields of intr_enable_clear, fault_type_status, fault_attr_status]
0x101C intr_enable_clear — Interrupt Enable Clear register
  [3] ? — Proxy0 access violation error enable clear. Write a 1 to clear the enable. Writing a 0 has no effect.
  [2] ? — Kick access violation error enable clear. Write a 1 to clear the enable. Writing a 0 has no effect.
  [1] ? — Addressing violation error enable clear. Write a 1 to clear the enable. Writing a 0 has no effect.
  [0] ? — Protection violation error enable clear. Write a 1 to clear the enable. Writing a 0 has no effect.
0x1020 eoi
  [7:0] ? — EOI vector value. Write this with interrupt distribution value in the chip.
0x1024 fault_address ro
  [31:0] ? — Fault Address.
0x1028 fault_type_status ro
  [6] ? — Non-secure access.
  [5:0] ? — Fault Type 10_0000 = Supervisor read fault - priv = 1 dir = 1 dtype != 1 01_0000 = Supervisor write fault - priv = 1 dir = 0 00_1000 = Supervisor execute fault - priv = 1 dir = 1 dtype = 1 00_0100 = User read fault - priv = 0 dir = 1 dtype = 1 00_0010 = User write fault - priv = 0 dir = 0 00_0001 = User execute fault - priv = 0 dir = 1 dtype = 1 00_0000 = No fault
0x102C fault_attr_status ro — Fault Attribute Status register
  [31:20] ? — XID.
  [19:8] ? — Route ID.
  [7:0] ? — Privilege ID.
0x1030 fault_clear wo
  [0] ? — Fault clear. Writing a 1 clears the current fault. Writing a 0 has no effect.
